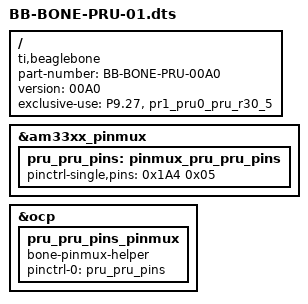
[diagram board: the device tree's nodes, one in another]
/*
* Copyright (C) 2013 Matt Ranostay <mranostay@gmail.com>
*
* This program is free software; you can redistribute it and/or modify
* it under the terms of the GNU General Public License version 2 as
* published by the Free Software Foundation.
*/

/*
Nov 18, 2016
Modified:  Neil Jubinville,  added bone-pinmux-helper and extra wrapper
*/


/dts-v1/;
/plugin/;

/ {
	compatible = "ti,beaglebone", "ti,beaglebone-black";

	/* identification */
	part-number = "BB-BONE-PRU-00A0";
	version = "00A0";

	/* state the resources this cape uses */
	exclusive-use =
		/* the pin header uses */
		"P9.27",	/* pru0: pr1_pru0_pru_r30_5 */
		/* the hardware IP uses */
		"pr1_pru0_pru_r30_5";

	fragment@0 {
		target = <&am33xx_pinmux>;
		__overlay__ {

			pru_pru_pins: pinmux_pru_pru_pins {
				pinctrl-single,pins = <
					0x1A4 0x05  // CS   P9_27 pr1_pru0_pru_r30_5, MODE5 | OUTPUT |
				>;
			};
		};
	};


        fragment@1 {
                target = <&ocp>;
                __overlay__ {
			pru_pru_pins_pinmux {
				compatible = "bone-pinmux-helper";
                        	status = "okay";
                        	pinctrl-names = "default";
                        	pinctrl-0 = <&pru_pru_pins>;
			};
                };
        };


};
